# SN32F700B register map
Vendor: SONiX Technology Co., Ltd.; Series: SN32F700B; File version: 2.1
CPU: CM0 r0p0, little endian, no MPU, no FPU, 2 interrupt priority bits
Registers are 32-bit, read-write, reset 0x0 unless marked. A register's access mark holds for its fields unless they carry their own. Offsets are from the block's base; [hi:lo] are bit positions; {n}, {i} and the like mark numbered series.

## SN_SYS1 — System Control Registers
Base 0x4005E000
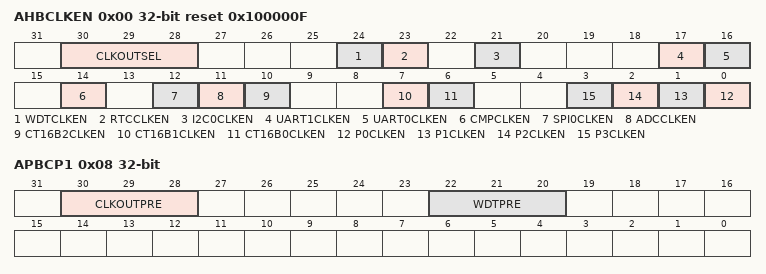
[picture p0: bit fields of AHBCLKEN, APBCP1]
0x00 AHBCLKEN reset 0x100000F — Offset:0x00 AHB Clock Enable Register
  [30:28] CLKOUTSEL — Clock output source selection
    0=000b (Disable); 1=001b (ILRC); 2=010b (ELS XTAL); 4=100b (HCLK); 5=101b (IHRC); 6=110b (EHS XTAL); 7=111b (PLL output)
  [24] WDTCLKEN — Enable AHB clock for WDT
    0=Disable; 1=Enable
  [23] RTCCLKEN — Enable AHB clock for RTC
    0=Disable; 1=Enable
  [21] I2C0CLKEN — Enable AHB clock for I2C0
    0=Disable; 1=Enable
  [17] UART1CLKEN — Enable AHB clock for UART1
    0=Disable; 1=Enable
  [16] UART0CLKEN — Enable AHB clock for UART0
    0=Disable; 1=Enable
  [14] CMPCLKEN — Enable AHB clock for CMP
    0=Disable; 1=Enable
  [12] SPI0CLKEN — Enable AHB clock for SPI0
    0=Disable; 1=Enable
  [11] ADCCLKEN — Enable AHB clock for ADC
    0=Disable; 1=Enable
  [10] CT16B2CLKEN — Enable AHB clock for CT16B2
    0=Disable; 1=Enable
  [7] CT16B1CLKEN — Enable AHB clock for CT16B1
    0=Disable; 1=Enable
  [6] CT16B0CLKEN — Enable AHB clock for CT16B0
    0=Disable; 1=Enable
  [n] P{n}CLKEN (n=0..3) — Enable AHB clock for P{n}
    0=Disable; 1=Enable
0x04 APBCP0 — Offset:0x04 APB Clock Prescale Register 0
  [18:16] ADCPRE — ADC APB clock source prescaler
    0=000b (HCLK/1); 1=001b (HCLK/2); 2=010b (HCLK/4); 3=011b (HCLK/8); 4=100b (HCLK/16)
0x08 APBCP1 — Offset:0x08 APB Clock Prescale Register 1
  [30:28] CLKOUTPRE — CLKOUT APB clock source prescaler
    0=000b (FCLKOUT/1); 1=001b (FCLKOUT/2); 2=010b (FCLKOUT/4); 3=011b (FCLKOUT/8); 4=100b (FCLKOUT/16); 5=101b (FCLKOUT/32); 6=110b (FCLKOUT/64); 7=111b (FCLKOUT/128)
  [22:20] WDTPRE — WDT APB clock source prescaler
    0=000b (WDT_PCLK = WDT clock source / 1); 1=001b (WDT_PCLK = WDT clock source / 2); 2=010b (WDT_PCLK = WDT clock source / 4); 3=011b (WDT_PCLK = WDT clock source / 8); 4=100b (WDT_PCLK = WDT clock source / 16); 5=101b (WDT_PCLK = WDT clock source / 32)

## SN_PMU — Power Management Unit
Base 0x40032000
{0x0+4i} BKP{i} (i=0..7) — Offset:{0x0+4i} PMU Backup Register {i}
  [7:0] BACKUPDATA — Data retained
0x40 CTRL — Offset:0x40 PMU Control Register
  [2:0] MODE — Low Power mode selection
    0=Disable Low-power mode; 2=Deep-sleep mode (WFI instruction will make MCU enter Deep-sleep mode); 4=Sleep mode (WFI instruction will make MCU enter Sleep mode)
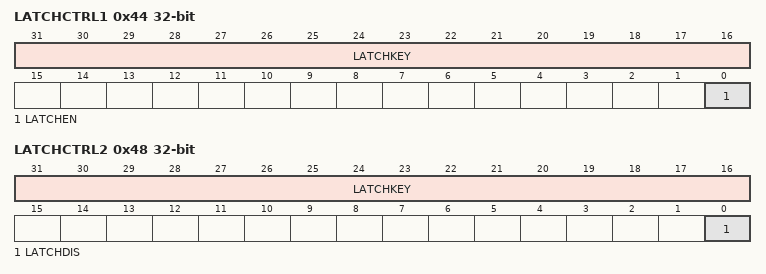
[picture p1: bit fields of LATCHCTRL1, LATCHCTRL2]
0x44 LATCHCTRL1 — Offset:0x44 PMU Latch Control Register 1
  [31:16] LATCHKEY wo — Latch register key
  [0] LATCHEN — Latch enable bit
    0=No effect; 1=Enable GPIO latch function
0x48 LATCHCTRL2 — Offset:0x48 PMU Latch Control Register 2
  [31:16] LATCHKEY wo — Latch register key
  [0] LATCHDIS — Latch disable bit
    0=No effect; 1=Disable GPIO latch function
0x4C LATCHST ro — Offset:0x4C PMU Latch Status Register
  [0] LATCHST — Latch status
    0=Not latched (GPIO is Not latched); 1=Latched (GPIO status is latched)

## SN_WDT — Watchdog Timer
Base 0x40010000
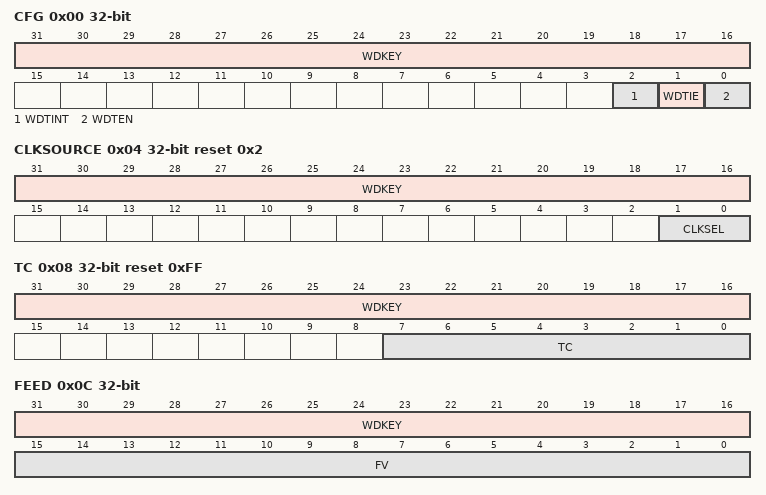
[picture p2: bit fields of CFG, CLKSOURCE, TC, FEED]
0x00 CFG — Offset:0x00 WDT Configuration Register
  [31:16] WDKEY wo — WDT register key
  [2] WDTINT — WDT interrupt flag
    0=No (No WDT time-out); 1=WDT time-out (WDT interrupt is triggered if WDTIE=1)
  [1] WDTIE — WDT interrupt enable
    0=Disable (WDT reset when WDT time-out); 1=Enable WDT interrupt
  [0] WDTEN — WDT enable
    0=Disable WDT; 1=Enable WDT
0x04 CLKSOURCE reset 0x2 — Offset:0x04 WDT Clock Source Register
  [31:16] WDKEY wo — WDT register key
  [1:0] CLKSEL — WDT clock source
    2=ILRC (WDT clock source=ILRC); 3=ELS XTAL (WDT clock source=ELS XTAL)
0x08 TC reset 0xFF — Offset:0x08 WDT Timer Constant Register
  [31:16] WDKEY wo — WDT register key
  [7:0] TC — Watchdog timer constant reload value
0x0C FEED wo — Offset:0x0C WDT Feed Register
  [31:16] WDKEY — WDT register key
  [15:0] FV — Watchdog feed value
